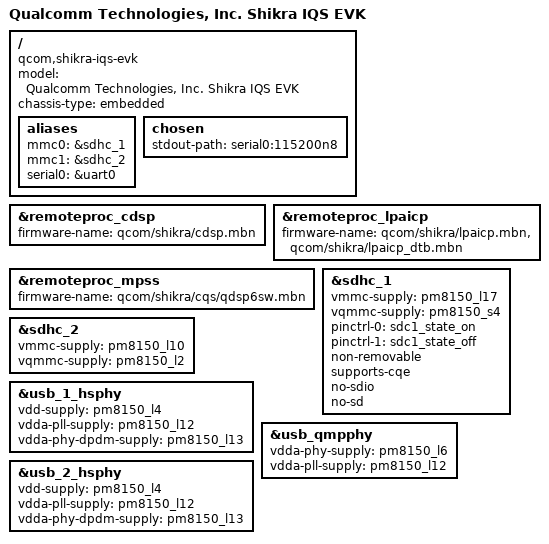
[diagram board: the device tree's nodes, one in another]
// SPDX-License-Identifier: BSD-3-Clause
/*
 * Copyright (c) Qualcomm Technologies, Inc. and/or its subsidiaries.
 */

/dts-v1/;

#include "shikra-iqs-som.dtsi"
#include "shikra-evk.dtsi"
#include <dt-bindings/gpio/gpio.h>

/ {
	model = "Qualcomm Technologies, Inc. Shikra IQS EVK";
	compatible = "qcom,shikra-iqs-evk", "qcom,shikra-iqs-som", "qcom,shikra";
	chassis-type = "embedded";

	aliases {
		mmc0 = &sdhc_1;
		mmc1 = &sdhc_2; /* SDC2 SD card slot */
		serial0 = &uart0;
	};

	chosen {
		stdout-path = "serial0:115200n8";
	};
};

&remoteproc_cdsp {
	firmware-name = "qcom/shikra/cdsp.mbn";

	status = "okay";
};

&remoteproc_lpaicp {
	firmware-name = "qcom/shikra/lpaicp.mbn",
			"qcom/shikra/lpaicp_dtb.mbn";

	status = "okay";
};

&remoteproc_mpss {
	firmware-name = "qcom/shikra/cqs/qdsp6sw.mbn";

	status = "okay";
};

&sdhc_1 {
	vmmc-supply = <&pm8150_l17>;
	vqmmc-supply = <&pm8150_s4>;

	pinctrl-0 = <&sdc1_state_on>;
	pinctrl-1 = <&sdc1_state_off>;
	pinctrl-names = "default", "sleep";

	non-removable;
	supports-cqe;
	no-sdio;
	no-sd;

	status = "okay";
};

&sdhc_2 {
	vmmc-supply = <&pm8150_l10>;
	vqmmc-supply = <&pm8150_l2>;

	status = "okay";
};

&usb_1_hsphy {
	vdd-supply = <&pm8150_l4>;
	vdda-pll-supply = <&pm8150_l12>;
	vdda-phy-dpdm-supply = <&pm8150_l13>;

	status = "okay";
};

&usb_qmpphy {
	vdda-phy-supply = <&pm8150_l6>;
	vdda-pll-supply = <&pm8150_l12>;

	status = "okay";
};

&usb_2_hsphy {
	vdd-supply = <&pm8150_l4>;
	vdda-pll-supply = <&pm8150_l12>;
	vdda-phy-dpdm-supply = <&pm8150_l13>;

	status = "okay";
};
